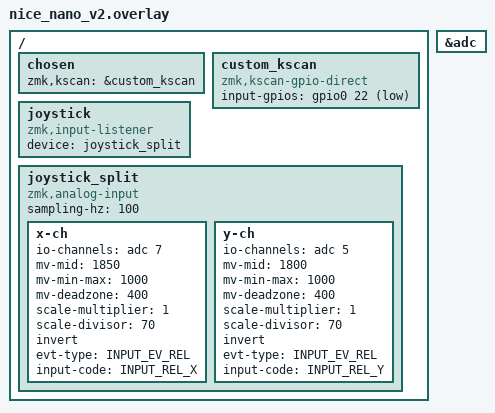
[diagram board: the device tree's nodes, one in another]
#include <zephyr/dt-bindings/input/input-event-codes.h>

/* 1. Enable the ADC hardware on the nice!nano */
&adc {
    status = "okay";
};

/* 2. Define the Joystick Input Listener */
/ {
    chosen {
        zmk,kscan = &custom_kscan;
    };

    custom_kscan: custom_kscan {
        compatible = "zmk,kscan-gpio-direct";
        input-gpios
            = <&gpio0 22 (GPIO_ACTIVE_LOW | GPIO_PULL_UP)>;
    };

    /* Define the input device (Physical Hardware) */
    joystick: joystick {
        compatible = "zmk,input-listener";
        device = <&joystick_split>; // Links to the split node below
    };  

    /* Define the analog sensor configuration */
    joystick_split: joystick_split {
        compatible = "zmk,analog-input";
        sampling-hz = <100>;
        x-ch {
            io-channels = <&adc 7>;
            mv-mid = <1850>;
		    mv-min-max = <1000>;
		    mv-deadzone = <400>;
		    scale-multiplier = <1>;
		    scale-divisor = <70>;
		    invert;
		    evt-type = <INPUT_EV_REL>;
		    input-code = <INPUT_REL_X>;
        };
        y-ch {
            io-channels = <&adc 5>;
            mv-mid = <1800>;
			mv-min-max = <1000>;
			mv-deadzone = <400>;
			scale-multiplier = <1>;
			scale-divisor = <70>;
			invert;
			evt-type = <INPUT_EV_REL>;
			input-code = <INPUT_REL_Y>;
        };

    };
};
